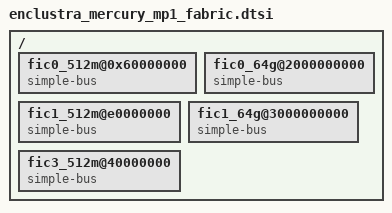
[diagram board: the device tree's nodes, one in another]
// SPDX-License-Identifier: (GPL-2.0+ OR MIT)
/*
 * Copyright (C) 2022 Enclustra GmbH
 * <info@enclustra.com>
 */

/ {
	/* FIC0 (AXI) at address 0x6000_0000 - 0x7FFF_FFFF */
	fic0_512m@0x60000000 {
		#address-cells = <1>;
		#size-cells = <1>;
		compatible = "simple-bus";
		ranges = <0x0 0x60000000 0x20000000>;
	};

	/* FIC0 (AXI) at address 0x20_0000_0000 - 0x2F_FFFF_FFFF */
	fic0_64g@2000000000 {
		#address-cells = <2>;
		#size-cells = <2>;
		compatible = "simple-bus";
		ranges = <0x0 0x0 0x20 0x00 0x10 0x00>;
	};

	/* FIC1 (AXI) at address 0xE000_0000 - 0xFFFF_FFFF */
	fic1_512m@e0000000 {
		#address-cells = <1>;
		#size-cells = <1>;
		compatible = "simple-bus";
		ranges = <0x0 0xe0000000 0x20000000>;
	};

	/* FIC1 (AXI) at address 0x30_0000_0000 - 0x3F_FFFF_FFFF */
	fic1_64g@3000000000 {
		#address-cells = <2>;
		#size-cells = <2>;
		compatible = "simple-bus";
		ranges = <0x0 0x0 0x30 0x00 0x10 0x00>;
	};

	/* FIC3 (APB) at address 0x40000000 - 0x5FFFFFFF */
	fic3_512m@40000000 {
		#address-cells = <1>;
		#size-cells = <1>;
		compatible = "simple-bus";
		ranges = <0x0 0x40000000 0x20000000>;
	};
};
